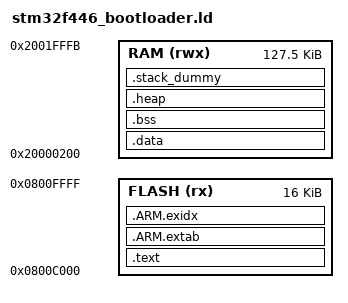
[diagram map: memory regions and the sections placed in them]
/*

See stm32f446.ld for the entire memory map.

*/

MEMORY
{
  FLASH (rx) : ORIGIN = 0x800c000, LENGTH = 0x4000
  RAM (rwx)  : ORIGIN = 0x20000200, LENGTH = 128k - (0x200+0x4)
}

ENTRY(MultiplexBootloader)

SECTIONS
{
    .text :
    {
        . = ALIGN(4);
        *bootloader.o(.multiplex_bootloader)
        KEEP(*bootloader.o(.text*))
        KEEP(*bootloader.o(.rodata*))
        *(.text*)
        *(.init)
        *(.fini)

        *(.rodata*)
        . = ALIGN(4);
    } >FLASH

    .ARM.extab :
    {
        *(.ARM.extab* .gnu.linkonce.armextab.*)
    } > FLASH

    __exidx_start = .;
    .ARM.exidx :
    {
        *(.ARM.exidx* .gnu.linkonce.armexidx.*)
    } > FLASH
    __exidx_end = .;

    __etext = .;
    _sidata = .;

    .data : AT (__etext)
    {
        __data_start__ = .;
        _sdata = .;
        *(vtable)
        *(.data*)

        . = ALIGN(8);
        /* preinit data */
        PROVIDE_HIDDEN (__preinit_array_start = .);
        KEEP(*(.preinit_array))
        PROVIDE_HIDDEN (__preinit_array_end = .);

        . = ALIGN(8);
        /* init data */
        PROVIDE_HIDDEN (__init_array_start = .);
        KEEP(*(SORT(.init_array.*)))
        KEEP(*(.init_array))
        PROVIDE_HIDDEN (__init_array_end = .);


        . = ALIGN(8);
        /* finit data */
        PROVIDE_HIDDEN (__fini_array_start = .);
        KEEP(*(SORT(.fini_array.*)))
        KEEP(*(.fini_array))
        PROVIDE_HIDDEN (__fini_array_end = .);

        KEEP(*(.jcr*))
        . = ALIGN(8);
        /* All data end */
        __data_end__ = .;
        _edata = .;

    } > RAM

    .bss :
    {
        . = ALIGN(8);
        __bss_start__ = .;
        _sbss = .;
        *(.bss*)
        *(COMMON)
        . = ALIGN(8);
        __bss_end__ = .;
        _ebss = .;
    } > RAM

    .heap (COPY):
    {
        __end__ = .;
        end = __end__;
        *(.heap*)
        __HeapLimit = .;
    } > RAM

    /* .stack_dummy section doesn't contains any symbols. It is only
     * used for linker to calculate size of stack sections, and assign
     * values to stack symbols later */
    .stack_dummy (COPY):
    {
        *(.stack*)
    } > RAM

    /* Set stack top to end of RAM, and stack limit move down by
     * size of stack_dummy section */
    __StackTop = ORIGIN(RAM) + LENGTH(RAM);
    _estack = __StackTop;
    __StackLimit = __StackTop - SIZEOF(.stack_dummy);
    PROVIDE(__stack = __StackTop);

    /* Check if data + heap + stack exceeds RAM limit */
    ASSERT(__StackLimit >= __HeapLimit, "region RAM overflowed with stack")
}
